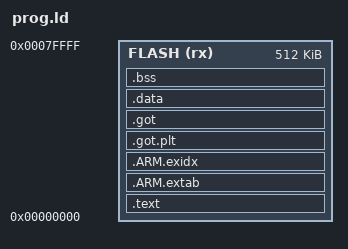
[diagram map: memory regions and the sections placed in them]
MEMORY
{
  FLASH (rx)    : ORIGIN = 0x00000000, LENGTH = 0x00080000 /* Flash, 512K */
}

SECTIONS
{
	.text :
	{
		KEEP(*(.jump_vector))
    __text_start__ = .;
		*(.text*)

		KEEP(*(.init))
		KEEP(*(.fini))

		/* .ctors */
		*crtbegin.o(.ctors)
		*crtbegin?.o(.ctors)
		*(EXCLUDE_FILE(*crtend?.o *crtend.o) .ctors)
		*(SORT(.ctors.*))
		*(.ctors)

		/* .dtors */
 		*crtbegin.o(.dtors)
 		*crtbegin?.o(.dtors)
 		*(EXCLUDE_FILE(*crtend?.o *crtend.o) .dtors)
 		*(SORT(.dtors.*))
 		*(.dtors)

		*(.rodata*)

		KEEP(*(.eh_frame*))
    __text_end__ = .;
	} > FLASH

	.ARM.extab :
	{
		*(.ARM.extab* .gnu.linkonce.armextab.*)
	} > FLASH

	__exidx_start = .;
	.ARM.exidx :
	{
		*(.ARM.exidx* .gnu.linkonce.armexidx.*)
	} > FLASH
	__exidx_end = .;

  .got.plt :
  {
    __got_plt_start__ = .;
    *(.got.plt)
    __got_plt_end__ = .;
  } > FLASH

  .got :
  {
    __got_start__ = .;
    *(.got)
    __got_end__ = .;
  } > FLASH

	.data :
	{
		__data_start__ = .;
		*(vtable)
		*(.data*)

		. = ALIGN(4);
		/* preinit data */
		PROVIDE_HIDDEN (__preinit_array_start = .);
		KEEP(*(.preinit_array))
		PROVIDE_HIDDEN (__preinit_array_end = .);

		. = ALIGN(4);
		/* init data */
		PROVIDE_HIDDEN (__init_array_start = .);
		KEEP(*(SORT(.init_array.*)))
		KEEP(*(.init_array))
		PROVIDE_HIDDEN (__init_array_end = .);


		. = ALIGN(4);
		/* finit data */
		PROVIDE_HIDDEN (__fini_array_start = .);
		KEEP(*(SORT(.fini_array.*)))
		KEEP(*(.fini_array))
		PROVIDE_HIDDEN (__fini_array_end = .);

		KEEP(*(.jcr*))
		. = ALIGN(4);
		/* All data end */
		__data_end__ = .;

	} > FLASH

	.bss :
	{
		__bss_start__ = .;
		*(.bss*)
		*(COMMON)
		__bss_end__ = .;
	} > FLASH

}
